AUTOSAR XML (schema 00049)
package /Application/DltConfig
  dlt log channel to process mapping DltLogChannelToProcessMapping_SOA_HVAC_TO_SOA_HVAC: dlt-log-channel=SOA_HVAC, process=SOA_HVAC
package /Application/Executable
  executable SOA_HVAC: category=APPLICATION_LEVEL, logging-behavior=USES-LOGGING, reporting-behavior=REPORTS-EXECUTION-STATE, version=1.0.0
    root sw component prototype AA: application-type=SOA_HVAC
package /Application/Manifest
  service instance to port prototype mapping SOA_HVAC_AA_PPort_SOA_HVAC: port-prototype=AA.PPort_SOA_HVAC, process=SOA_HVAC, service-instance=Provider_SoaHvac
  service instance to port prototype mapping SOA_HVAC_AA_RPort_Zone1VehicleInfo: port-prototype=AA.RPort_Zone1VehicleInfo, process=SOA_HVAC, service-instance=Consumer_SoaHvac_VehicleInfo
  service instance to port prototype mapping SOA_HVAC_AA_RPort_Zone5_HVAC: port-prototype=AA.RPort_Zone5_HVAC, process=SOA_HVAC, service-instance=Consumer_Zone5Hvac
package /Application/Package/SOA_HVAC/SoftwareCluster_1_0_0
  software cluster SOA_HVAC_SoftwareCluster: category=APPLICATION_LAYER, contained-ar-element=SOA_HVAC, contained-package-element=[SOA_HVAC_AA_PPort_SOA_HVAC, SOA_HVAC_AA_RPort_Zone1VehicleInfo, SOA_HVAC_AA_RPort_Zone5_HVAC], contained-process=SOA_HVAC, vendor-id=79, vendor-signature=ParaCertificate, version=1.0.0
package /Application/Package/SOA_HVAC/SoftwareCluster_1_0_1
  software cluster SOA_HVAC_SoftwareCluster: category=APPLICATION_LAYER, contained-ar-element=SOA_HVAC, contained-package-element=[SOA_HVAC_AA_PPort_SOA_HVAC, SOA_HVAC_AA_RPort_Zone1VehicleInfo, SOA_HVAC_AA_RPort_Zone5_HVAC], contained-process=SOA_HVAC, vendor-id=79, vendor-signature=ParaCertificate, version=1.0.1
package /Application/Package/SOA_HVAC/SoftwareCluster_1_0_2
  software cluster SOA_HVAC_SoftwareCluster: category=APPLICATION_LAYER, contained-ar-element=SOA_HVAC, contained-package-element=[SOA_HVAC_AA_PPort_SOA_HVAC, SOA_HVAC_AA_RPort_Zone1VehicleInfo, SOA_HVAC_AA_RPort_Zone5_HVAC], contained-process=SOA_HVAC, vendor-id=79, vendor-signature=ParaCertificate, version=1.0.2
package /Application/Package/SOA_HVAC/SoftwarePackage
  software package SOA_HVAC_InstallSoftwarePackage_1_0_0: action-type=INSTALL, compressed-software-package-size=0, maximum-supported-ucm-version=1.0.0, minimum-supported-ucm-version=1.0.0, packager-id=79, packager-signature=ParaCertificate, post-verification-reboot=false, pre-activate=SC.Off, pre-activation-reboot=false, software-cluster=SoftwareCluster_1_0_0/SOA_HVAC_SoftwareCluster, uncompressed-software-cluster-size=0, verify=SC.Verify
  software package SOA_HVAC_RemoveSoftwarePackage_1_0_2: action-type=REMOVE, compressed-software-package-size=0, maximum-supported-ucm-version=1.0.0, minimum-supported-ucm-version=1.0.0, packager-id=79, packager-signature=ParaCertificate, post-verification-reboot=false, pre-activate=SC.Off, pre-activation-reboot=false, software-cluster=SoftwareCluster_1_0_2/SOA_HVAC_SoftwareCluster, uncompressed-software-cluster-size=0, verify=SC.Verify
  software package SOA_HVAC_UpdateSoftwarePackage_1_0_1: action-type=UPDATE, compressed-software-package-size=0, maximum-supported-ucm-version=1.0.0, minimum-supported-ucm-version=1.0.0, packager-id=79, packager-signature=ParaCertificate, post-verification-reboot=false, pre-activate=SC.Off, pre-activation-reboot=false, software-cluster=SoftwareCluster_1_0_1/SOA_HVAC_SoftwareCluster, uncompressed-software-cluster-size=0, verify=SC.Verify
package /Application/Package/SOA_HVAC/VehiclePackage
  vehicle package SOA_HVAC_InstallVehiclePackage_1_0_0: vehicle-driver-notification{approval-required=true, notification-state=PROCESS}, packager-signature=ParaCertificate
    rollout-qualifications:
      vehicle rollout step RolloutQualification0
        ucm-processings:
          ucm step UcmProcessing0: ucm=SOA_HVAC_InstallVehiclePackage_1_0_0/EEVP_UCM
            software package step SoftwarePackageStep0: process=SOA_HVAC_InstallSoftwarePackage_1_0_0, transfers=software-package-storing={storing=UCM, transfer=SOA_HVAC_InstallSoftwarePackage_1_0_0}
    ucm description EEVP_UCM: identifier=EEVP_UCM
  vehicle package SOA_HVAC_RemoveVehiclePackage_1_0_2: vehicle-driver-notification{approval-required=false, notification-state=PROCESS}, packager-signature=ParaCertificate
    rollout-qualifications:
      vehicle rollout step RolloutQualification0
        ucm-processings:
          ucm step UcmProcessing0: ucm=SOA_HVAC_RemoveVehiclePackage_1_0_2/EEVP_UCM
            software package step SoftwarePackageStep0: process=SOA_HVAC_RemoveSoftwarePackage_1_0_2, transfers=software-package-storing={storing=UCM, transfer=SOA_HVAC_RemoveSoftwarePackage_1_0_2}
    ucm description EEVP_UCM: identifier=EEVP_UCM
  vehicle package SOA_HVAC_UpdateVehiclePackage_1_0_1: vehicle-driver-notification{approval-required=true, notification-state=PROCESS}, packager-signature=ParaCertificate
    rollout-qualifications:
      vehicle rollout step RolloutQualification0
        ucm-processings:
          ucm step UcmProcessing0: ucm=SOA_HVAC_UpdateVehiclePackage_1_0_1/EEVP_UCM
            software package step SoftwarePackageStep0: process=SOA_HVAC_UpdateSoftwarePackage_1_0_1, transfers=software-package-storing={storing=UCM, transfer=SOA_HVAC_UpdateSoftwarePackage_1_0_1}
    ucm description EEVP_UCM: identifier=EEVP_UCM
package /Application/Process
  process SOA_HVAC: executable=SOA_HVAC, state-dependent-startup-config{function-group-state=[SC.On, SC.Verify], resource-group=DefaultResourceGroup, startup-config=SOA}
    process state machine SOA_HVAC: type=ProcessState
package /Application/SwComponent
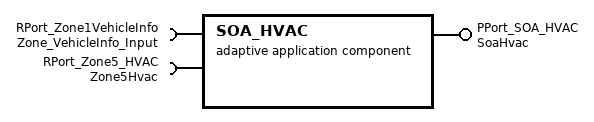
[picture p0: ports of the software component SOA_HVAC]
  adaptive application sw component type SOA_HVAC
    provide port PPort_SOA_HVAC: provided-interface=SoaHvac
    require port RPort_Zone1VehicleInfo: required-interface=Zone_VehicleInfo_Input
    require port RPort_Zone5_HVAC: required-interface=Zone5Hvac
